# STM32H7RSxx register map
File version: 0.2
CPU: CM7 r0p1, little endian, MPU, FPU, 4 interrupt priority bits
Registers are 32-bit, read-write, reset 0x0 unless marked. A register's access mark holds for its fields unless they carry their own. Offsets are from the block's base; [hi:lo] are bit positions; 'fields as' and 'values as' point back to an identical list.

## LPTIM1 — Low power timer
Base 0x40002400
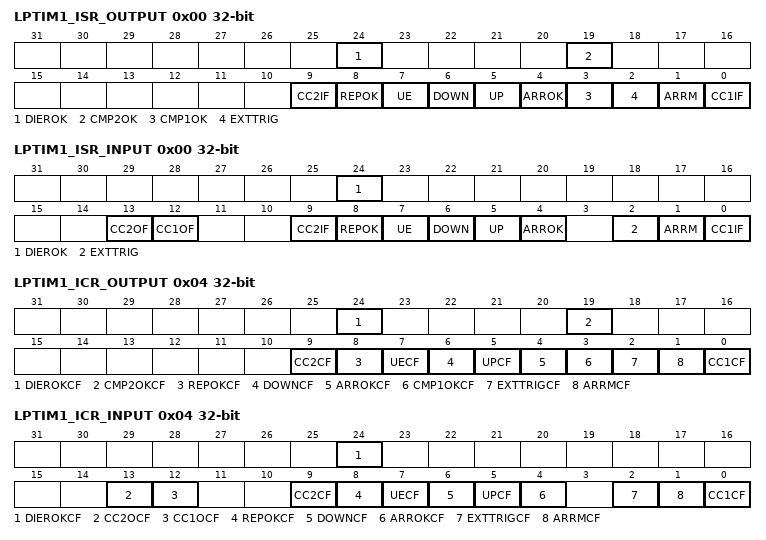
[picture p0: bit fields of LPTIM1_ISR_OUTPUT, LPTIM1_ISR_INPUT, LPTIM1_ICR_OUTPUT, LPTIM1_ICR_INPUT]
0x00 LPTIM1_ISR_OUTPUT ro — LPTIM1 interrupt and status register
  [24] DIEROK — Interrupt enable register update OK DIEROK is set by hardware to inform application that the APB bus write operation to the LPTIM_DIER register has been successfully completed. DIEROK flag can be cleared by writing 1 to the DIEROKCF bit in the LPTIM_ICR register.
  [19] CMP2OK — Compare register 2 update OK CMP2OK is set by hardware to inform application that the APB bus write operation to the LPTIM_CCR2 register has been successfully completed. CMP2OK flag can be cleared by writing 1 to the CMP2OKCF bit in the LPTIM_ICR register. Note: If LPTIM does not implement at least 2 channels this bit is reserved. Refer to Section 26.3.
  [9] CC2IF — Compare 2 interrupt flag If channel CC2 is configured as output: The CC2IF flag is set by hardware to inform application that LPTIM_CNT register value matches the compare register's value. CC2IF flag can be cleared by writing 1 to the CC2CF bit in the LPTIM_ICR register. Note: If LPTIM does not implement at least 2 channels this bit is reserved. Refer to Section 26.3.
    0=No match; 1=The content of the counter LPTIM_CNT register value has matched the LPTIM_CCR2 register's value
  [8] REPOK — Repetition register update OK REPOK is set by hardware to inform application that the APB bus write operation to the LPTIM_RCR register has been successfully completed. REPOK flag can be cleared by writing 1 to the REPOKCF bit in the LPTIM_ICR register.
  [7] UE — LPTIM update event occurred UE is set by hardware to inform application that an update event was generated. The corresponding interrupt or DMA request is generated if enabled. UE flag can be cleared by writing 1 to the UECF bit in the LPTIM_ICR register. The UE flag is automatically cleared by hardware once the LPTIM_ARR register is written by any bus master like CPU or DMA.
  [6] DOWN — Counter direction change up to down In Encoder mode, DOWN bit is set by hardware to inform application that the counter direction has changed from up to down. DOWN flag can be cleared by writing 1 to the DOWNCF bit in the LPTIM_ICR register. Note: If the LPTIM does not support encoder mode feature, this bit is reserved. Refer to Section 26.3.
  [5] UP — Counter direction change down to up In Encoder mode, UP bit is set by hardware to inform application that the counter direction has changed from down to up. UP flag can be cleared by writing 1 to the UPCF bit in the LPTIM_ICR register. Note: If the LPTIM does not support encoder mode feature, this bit is reserved. Refer to Section 26.3.
  [4] ARROK — Autoreload register update OK ARROK is set by hardware to inform application that the APB bus write operation to the LPTIM_ARR register has been successfully completed. ARROK flag can be cleared by writing 1 to the ARROKCF bit in the LPTIM_ICR register.
  [3] CMP1OK — Compare register 1 update OK CMP1OK is set by hardware to inform application that the APB bus write operation to the LPTIM_CCR1 register has been successfully completed. CMP1OK flag can be cleared by writing 1 to the CMP1OKCF bit in the LPTIM_ICR register.
  [2] EXTTRIG — External trigger edge event EXTTRIG is set by hardware to inform application that a valid edge on the selected external trigger input has occurred. If the trigger is ignored because the timer has already started, then this flag is not set. EXTTRIG flag can be cleared by writing 1 to the EXTTRIGCF bit in the LPTIM_ICR register.
  [1] ARRM — Autoreload match ARRM is set by hardware to inform application that LPTIM_CNT register’s value reached the LPTIM_ARR register’s value. ARRM flag can be cleared by writing 1 to the ARRMCF bit in the LPTIM_ICR register.
  [0] CC1IF — Compare 1 interrupt flag If channel CC1 is configured as output: The CC1IF flag is set by hardware to inform application that LPTIM_CNT register value matches the compare register's value. CC1IF flag can be cleared by writing 1 to the CC1CF bit in the LPTIM_ICR register.
    0=No match; 1=The content of the counter LPTIM_CNT register value has matched the LPTIM_CCR1 register's value
0x00 LPTIM1_ISR_INPUT ro (alternate view of LPTIM1_ISR_OUTPUT) — LPTIM1 interrupt and status register
  [24] DIEROK — Interrupt enable register update OK DIEROK is set by hardware to inform application that the APB bus write operation to the LPTIM_DIER register has been successfully completed. DIEROK flag can be cleared by writing 1 to the DIEROKCF bit in the LPTIM_ICR register.
  [13] CC2OF — Capture 2 over-capture flag This flag is set by hardware only when the corresponding channel is configured in input capture mode. It is cleared by software by writing 1 to the CC2OCF bit in the LPTIM_ICR register. Note: If LPTIM does not implement at least 2 channels this bit is reserved. Refer to Section 26.3.
    0=No over-capture has been detected; 1=The counter value has been captured in LPTIM_CCR2 register while CC2IF flag was already set
  [12] CC1OF — Capture 1 over-capture flag This flag is set by hardware only when the corresponding channel is configured in input capture mode. It is cleared by software by writing 1 to the CC1OCF bit in the LPTIM_ICR register. Note: If LPTIM does not implement at least 1 channel this bit is reserved. Refer to Section 26.3.
    0=No over-capture has been detected; 1=The counter value has been captured in LPTIM_CCR1 register while CC1IF flag was already set
  [9] CC2IF — Capture 2 interrupt flag If channel CC2 is configured as input: CC2IF is set by hardware to inform application that the current value of the counter is captured in LPTIM_CCR2 register. The corresponding interrupt or DMA request is generated if enabled. The CC2OF flag is set if the CC2IF flag was already high. Note: If LPTIM does not implement at least 2 channels this bit is reserved. Refer to Section 26.3.
    0=No input capture occurred; 1=The counter value has been captured in the LPTIM_CCR2 register. (An edge has been detected on IC2 which matches the selected polarity). The CC2IF flag is automatically cleared by hardware once the captured value is read (CPU or DMA). The CC2IF flag can be cleared by writing 1 to the CC2CF bit in the LPTIM_ICR register.
  [8] REPOK — Repetition register update OK REPOK is set by hardware to inform application that the APB bus write operation to the LPTIM_RCR register has been successfully completed. REPOK flag can be cleared by writing 1 to the REPOKCF bit in the LPTIM_ICR register.
  [7] UE — LPTIM update event occurred UE is set by hardware to inform application that an update event was generated. UE flag can be cleared by writing 1 to the UECF bit in the LPTIM_ICR register.
  [6] DOWN — Counter direction change up to down In Encoder mode, DOWN bit is set by hardware to inform application that the counter direction has changed from up to down. DOWN flag can be cleared by writing 1 to the DOWNCF bit in the LPTIM_ICR register. Note: If the LPTIM does not support encoder mode feature, this bit is reserved. Refer to Section 26.3.
  [5] UP — Counter direction change down to up In Encoder mode, UP bit is set by hardware to inform application that the counter direction has changed from down to up. UP flag can be cleared by writing 1 to the UPCF bit in the LPTIM_ICR register. Note: If the LPTIM does not support encoder mode feature, this bit is reserved. Refer to Section 26.3.
  [4] ARROK — Autoreload register update OK ARROK is set by hardware to inform application that the APB bus write operation to the LPTIM_ARR register has been successfully completed. ARROK flag can be cleared by writing 1 to the ARROKCF bit in the LPTIM_ICR register.
  [2] EXTTRIG — External trigger edge event EXTTRIG is set by hardware to inform application that a valid edge on the selected external trigger input has occurred. If the trigger is ignored because the timer has already started, then this flag is not set. EXTTRIG flag can be cleared by writing 1 to the EXTTRIGCF bit in the LPTIM_ICR register.
  [1] ARRM — Autoreload match ARRM is set by hardware to inform application that LPTIM_CNT register’s value reached the LPTIM_ARR register’s value. ARRM flag can be cleared by writing 1 to the ARRMCF bit in the LPTIM_ICR register.
  [0] CC1IF — capture 1 interrupt flag If channel CC1 is configured as input: CC1IF is set by hardware to inform application that the current value of the counter is captured in LPTIM_CCR1 register. The corresponding interrupt or DMA request is generated if enabled. The CC1OF flag is set if the CC1IF flag was already high.
    0=No input capture occurred; 1=The counter value has been captured in the LPTIM_CCR1 register. (An edge has been detected on IC1 which matches the selected polarity). The CC1IF flag is automatically cleared by hardware once the captured value is read (CPU or DMA).CC1IF flag can be cleared by writing 1 to the CC1CF bit in the LPTIM_ICR register.
0x04 LPTIM1_ICR_OUTPUT wo — LPTIM1 interrupt clear register
  [24] DIEROKCF — Interrupt enable register update OK clear flag Writing 1 to this bit clears the DIEROK flag in the LPTIM_ISR register.
  [19] CMP2OKCF — Compare register 2 update OK clear flag Writing 1 to this bit clears the CMP2OK flag in the LPTIM_ISR register. Note: If LPTIM does not implement at least 2 channels this bit is reserved. Refer to Section 26.3.
  [9] CC2CF — Capture/compare 2 clear flag Writing 1 to this bit clears the CC2IF flag in the LPTIM_ISR register. Note: If LPTIM does not implement at least 2 channels this bit is reserved. Refer to Section 26.3.
  [8] REPOKCF — Repetition register update OK clear flag Writing 1 to this bit clears the REPOK flag in the LPTIM_ISR register.
  [7] UECF — Update event clear flag Writing 1 to this bit clear the UE flag in the LPTIM_ISR register.
  [6] DOWNCF — Direction change to down clear flag Writing 1 to this bit clear the DOWN flag in the LPTIM_ISR register. Note: If the LPTIM does not support encoder mode feature, this bit is reserved. Refer to Section 26.3.
  [5] UPCF — Direction change to UP clear flag Writing 1 to this bit clear the UP flag in the LPTIM_ISR register. Note: If the LPTIM does not support encoder mode feature, this bit is reserved. Refer to Section 26.3.
  [4] ARROKCF — Autoreload register update OK clear flag Writing 1 to this bit clears the ARROK flag in the LPTIM_ISR register
  [3] CMP1OKCF — Compare register 1 update OK clear flag Writing 1 to this bit clears the CMP1OK flag in the LPTIM_ISR register.
  [2] EXTTRIGCF — External trigger valid edge clear flag Writing 1 to this bit clears the EXTTRIG flag in the LPTIM_ISR register
  [1] ARRMCF — Autoreload match clear flag Writing 1 to this bit clears the ARRM flag in the LPTIM_ISR register
  [0] CC1CF — Capture/compare 1 clear flag Writing 1 to this bit clears the CC1IF flag in the LPTIM_ISR register.
0x04 LPTIM1_ICR_INPUT wo (alternate view of LPTIM1_ICR_OUTPUT) — LPTIM1 interrupt clear register
  [24] DIEROKCF — Interrupt enable register update OK clear flag Writing 1 to this bit clears the DIEROK flag in the LPTIM_ISR register.
  [13] CC2OCF — Capture/compare 2 over-capture clear flag Writing 1 to this bit clears the CC2OF flag in the LPTIM_ISR register. Note: If LPTIM does not implement at least 2 channels this bit is reserved. Refer to Section 26.3.
  [12] CC1OCF — Capture/compare 1 over-capture clear flag Writing 1 to this bit clears the CC1OF flag in the LPTIM_ISR register. Note: If LPTIM does not implement at least 1 channel this bit is reserved. Refer to Section 26.3.
  [9] CC2CF — Capture/compare 2 clear flag Writing 1 to this bit clears the CC2IF flag in the LPTIM_ISR register. Note: If LPTIM does not implement at least 2 channels this bit is reserved. Refer to Section 26.3.
  [8] REPOKCF — Repetition register update OK clear flag Writing 1 to this bit clears the REPOK flag in the LPTIM_ISR register.
  [7] UECF — Update event clear flag Writing 1 to this bit clear the UE flag in the LPTIM_ISR register.
  [6] DOWNCF — Direction change to down clear flag Writing 1 to this bit clear the DOWN flag in the LPTIM_ISR register. Note: If the LPTIM does not support encoder mode feature, this bit is reserved. Refer to Section 26.3.
  [5] UPCF — Direction change to UP clear flag Writing 1 to this bit clear the UP flag in the LPTIM_ISR register. Note: If the LPTIM does not support encoder mode feature, this bit is reserved. Refer to Section 26.3.
  [4] ARROKCF — Autoreload register update OK clear flag Writing 1 to this bit clears the ARROK flag in the LPTIM_ISR register
  [2] EXTTRIGCF — External trigger valid edge clear flag Writing 1 to this bit clears the EXTTRIG flag in the LPTIM_ISR register
  [1] ARRMCF — Autoreload match clear flag Writing 1 to this bit clears the ARRM flag in the LPTIM_ISR register
  [0] CC1CF — Capture/compare 1 clear flag Writing 1 to this bit clears the CC1IF flag in the LPTIM_ISR register.
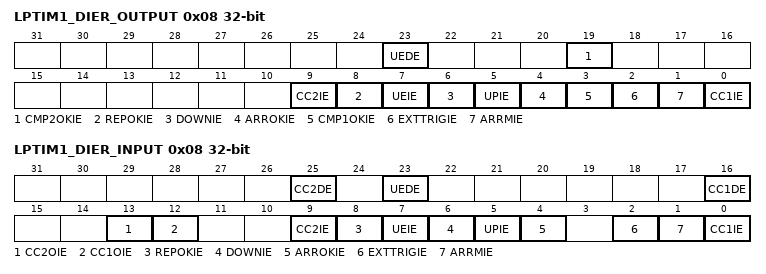
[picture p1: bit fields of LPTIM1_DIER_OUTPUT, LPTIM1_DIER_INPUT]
0x08 LPTIM1_DIER_OUTPUT — LPTIM1 interrupt enable register
  [23] UEDE — Update event DMA request enable Note: If LPTIM does not implement at least 1 channel this bit is reserved. Refer to Section 26.3.
    0=UE DMA request disabled. Writing '0' to the UEDE bit resets the associated ue_dma_req signal.; 1=UE DMA request enabled
  [19] CMP2OKIE — Compare register 2 update OK interrupt enable Note: If LPTIM does not implement at least 2 channels this bit is reserved. Refer to Section 26.3.
    0=CMPOK register 2 interrupt disabled; 1=CMPOK register 2 interrupt enabled
  [9] CC2IE — Capture/compare 2 interrupt enable Note: If LPTIM does not implement at least 2 channels this bit is reserved. Refer to Section 26.3.
    0=Capture/compare 2 interrupt disabled; 1=Capture/compare 2 interrupt enabled
  [8] REPOKIE — Repetition register update OK interrupt Enable
    0=Repetition register update OK interrupt disabled; 1=Repetition register update OK interrupt enabled
  [7] UEIE — Update event interrupt enable
    0=Update event interrupt disabled; 1=Update event interrupt enabled
  [6] DOWNIE — Direction change to down Interrupt Enable Note: If the LPTIM does not support encoder mode feature, this bit is reserved. Refer to Section 26.3.
    0=DOWN interrupt disabled; 1=DOWN interrupt enabled
  [5] UPIE — Direction change to UP Interrupt Enable Note: If the LPTIM does not support encoder mode feature, this bit is reserved. Refer to Section 26.3.
    0=UP interrupt disabled; 1=UP interrupt enabled
  [4] ARROKIE — Autoreload register update OK Interrupt Enable
    0=ARROK interrupt disabled; 1=ARROK interrupt enabled
  [3] CMP1OKIE — Compare register 1 update OK interrupt enable
    0=CMPOK register 1 interrupt disabled; 1=CMPOK register 1 interrupt enabled
  [2] EXTTRIGIE — External trigger valid edge Interrupt Enable
    0=EXTTRIG interrupt disabled; 1=EXTTRIG interrupt enabled
  [1] ARRMIE — Autoreload match Interrupt Enable
    0=ARRM interrupt disabled; 1=ARRM interrupt enabled
  [0] CC1IE — Capture/compare 1 interrupt enable
    0=Capture/compare 1 interrupt disabled; 1=Capture/compare 1 interrupt enabled
0x08 LPTIM1_DIER_INPUT (alternate view of LPTIM1_DIER_OUTPUT) — LPTIM1 interrupt enable register
  [25] CC2DE — Capture/compare 2 DMA request enable Note: If LPTIM does not implement at least 2 channels this bit is reserved. Refer to Section 26.3.
    0=CC2 DMA request disabled. Writing '0' to the CC2DE bit resets the associated ic2_dma_req signal.; 1=CC2 DMA request enabled
  [23] UEDE — Update event DMA request enable Note: If LPTIM does not implement at least 1 channel this bit is reserved. Refer to Section 26.3.
    values as LPTIM1_DIER_OUTPUT.UEDE
  [16] CC1DE — Capture/compare 1 DMA request enable Note: If LPTIM does not implement at least 1 channel this bit is reserved. Refer to Section 26.3.
    0=CC1 DMA request disabled. Writing '0' to the CC1DE bit resets the associated ic1_dma_req signal.; 1=CC1 DMA request enabled
  [13] CC2OIE — Capture/compare 2 over-capture interrupt enable Note: If LPTIM does not implement at least 2 channels this bit is reserved. Refer to Section 26.3.
    0=CC2 over-capture interrupt disabled; 1=CC2 over-capture interrupt enabled
  [12] CC1OIE — Capture/compare 1 over-capture interrupt enable Note: If LPTIM does not implement at least 1 channel this bit is reserved. Refer to Section 26.3.
    0=CC1 over-capture interrupt disabled; 1=CC1 over-capture interrupt enabled
  [9] CC2IE — Capture/compare 2 interrupt enable Note: If LPTIM does not implement at least 2 channels this bit is reserved. Refer to Section 26.3.
    values as LPTIM1_DIER_OUTPUT.CC2IE
  [8] REPOKIE — Repetition register update OK interrupt Enable
    values as LPTIM1_DIER_OUTPUT.REPOKIE
  [7] UEIE — Update event interrupt enable
    values as LPTIM1_DIER_OUTPUT.UEIE
  [6] DOWNIE — Direction change to down Interrupt Enable Note: If the LPTIM does not support encoder mode feature, this bit is reserved. Refer to Section 26.3.
    0=DOWN interrupt disabled; 1=DOWN interrupt enabled
  [5] UPIE — Direction change to UP Interrupt Enable Note: If the LPTIM does not support encoder mode feature, this bit is reserved. Refer to Section 26.3.
    0=UP interrupt disabled; 1=UP interrupt enabled
  [4] ARROKIE — Autoreload register update OK Interrupt Enable
    0=ARROK interrupt disabled; 1=ARROK interrupt enabled
  [2] EXTTRIGIE — External trigger valid edge Interrupt Enable
    0=EXTTRIG interrupt disabled; 1=EXTTRIG interrupt enabled
  [1] ARRMIE — Autoreload match Interrupt Enable
    0=ARRM interrupt disabled; 1=ARRM interrupt enabled
  [0] CC1IE — Capture/compare 1 interrupt enable
    values as LPTIM1_DIER_OUTPUT.CC1IE

## LPTIM2 — Low power timer
Base 0x58002400
Registers as LPTIM1 (with LPTIM1 read as LPTIM2).

## LPTIM3 — Low power timer
Base 0x58002800
Registers as LPTIM1 (with LPTIM1 read as LPTIM3).
